# S32K324_M7 register map
Vendor: NXP Semiconductors; File version: 1.1
CPU: CM7 r0p1, little endian, MPU, FPU, VTOR, 4 interrupt priority bits
Registers are 32-bit, read-write, reset 0x0 unless marked. A register's access mark holds for its fields unless they carry their own. Offsets are from the block's base; [hi:lo] are bit positions; {n}, {i} and the like mark numbered series; 'fields as' and 'values as' point back to an identical list.

## VIRT_WRAPPER — VIRT_WRAPPER memory map
Base 0x402A8000
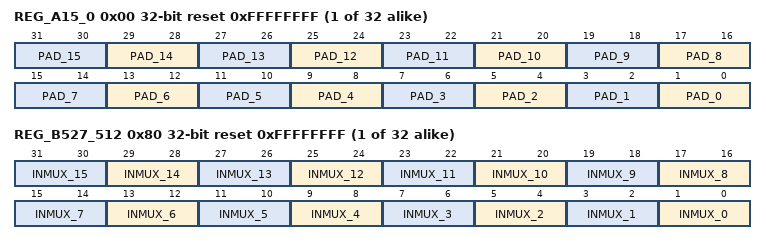
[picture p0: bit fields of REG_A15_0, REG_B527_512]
0x00 REG_A{x} (x=15_0,31_16,47_32,63_48,79_64,95_80,111_96,127_112,143_128,159_144,175_160,191_176,207_192,223_208,239_224,255_240,271_256,287_272,303_288,319_304,335_320,351_336,367_352,383_368,399_384,415_400,431_416,447_432,463_448,479_464,495_480,511_496; step 0x4) reset 0xFFFFFFFF — Parameter_n Register
  [2n+1:2n] PAD_{n} (n=0..15)
0x80 REG_B{x} (x=527_512,543_528,559_544,575_560,591_576,607_592,623_608,639_624,655_640,671_656,687_672,703_688,719_704,735_720,751_736,767_752,783_768,799_784,815_800,831_816,847_832,863_848,879_864,895_880,911_896,927_912,943_928,959_944,975_960,991_976,1007_992,1023_1008; step 0x4) reset 0xFFFFFFFF — Parameter_n Register
  [2n+1:2n] INMUX_{n} (n=0..15)
0x100 REG_C1039_1024 reset 0xFFFFFFFF — Parameter_n Register
  [1:0] INTC_CTRL — Interrupt register control
0x104 REG_D1055_1040 reset 0xFFFFFFFF — Parameter_n Register
  [31:30] REG_GCR — GCR Register Of REG_PROT

## WKPU
Base 0x402B4000
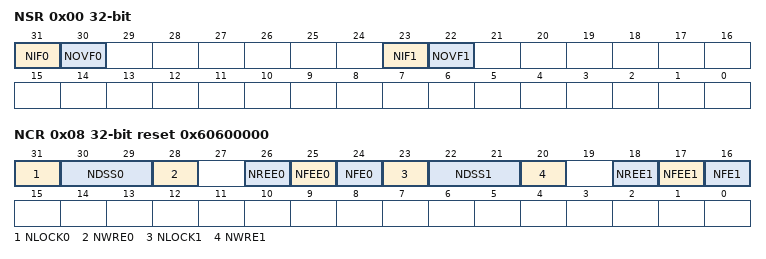
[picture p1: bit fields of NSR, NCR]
0x00 NSR write-1-clears — NMI Status Flag Register
  [31] NIF0 write-1-clears — NMI Status Flag 0
  [30] NOVF0 write-1-clears — NMI Overrun Status Flag 0
    0=No overrun has occurred on NMI input 0; 1=An overrun has occurred on NMI input 0
  [23] NIF1 write-1-clears — NMI Status Flag 1
    0=No event has occurred on the pad; 1=An event as defined by NREE1 and NFEE1 has occurred
  [22] NOVF1 write-1-clears — NMI Overrun Status Flag 1
    0=No overrun has occurred on NMI input 1; 1=An overrun has occurred on NMI input 1
0x08 NCR reset 0x60600000 — NMI Configuration Register
  [31] NLOCK0 — NMI Configuration Lock Register 0
  [30:29] NDSS0 — NMI Destination Source Select 0
    0=Non-maskable interrupt
  [28] NWRE0 — NMI Wakeup Request Enable 0
    0=System wakeup requests from the corresponding NIF0 field are disabled; 1=Causes a system wakeup request when NIF0 = 1 or NOVF0 = 1
  [26] NREE0 — NMI Rising-Edge Events Enable 0
    0=Rising-edge event is disabled; 1=Rising-edge event is enabled
  [25] NFEE0 — NMI Falling-edge Events Enable 0
  [24] NFE0 — NMI Filter Enable 0
    0=Filter is disabled; 1=Filter is enabled
  [23] NLOCK1 — NMI Configuration Lock Register 1
  [22:21] NDSS1 — NMI Destination Source Select 1
    0=Non-maskable interrupt
  [20] NWRE1 — NMI Wakeup Request Enable 1
    0=System wakeup requests from the corresponding NIF1 field are disabled; 1=Causes a system wakeup request when NIF1 = 1 or NOVF1 = 1
  [18] NREE1 — NMI Rising-Edge Events Enable 1
    values as NREE0
  [17] NFEE1 — NMI Falling-Edge Events Enable 1
  [16] NFE1 — NMI Filter Enable 1
    0=Filter is disabled; 1=Filter is enabled
0x14 WISR write-1-clears — Wakeup/Interrupt Status Flag Register
  [31:0] EIF write-1-clears — External Wakeup/Interrupt Status Flag x
0x18 IRER — Interrupt Request Enable Register
  [31:0] EIRE — External Interrupt Request Enable x
0x1C WRER — Wakeup Request Enable Register
  [31:0] WRE — External Wakeup Request Enable x
0x28 WIREER — Wakeup/Interrupt Rising-Edge Event Enable Register
  [31:0] IREE — External Interrupt Rising-edge Events Enable x
0x2C WIFEER — Wakeup/Interrupt Falling-Edge Event Enable Register
  [31:0] IFEEx — External Interrupt Falling-edge Events Enable x
0x30 WIFER — Wakeup/Interrupt Filter Enable Register
  [31:0] IFE — External Interrupt Filter Enable x
0x54 WISR_64 write-1-clears — Wakeup/Interrupt Status Flag Register
  [31:0] EIF_1 write-1-clears — External Wakeup/Interrupt Status Flag x
0x58 IRER_64 — Interrupt Request Enable Register
  [31:0] EIRE_1 — External Interrupt Request Enable x
0x5C WRER_64 — Wakeup Request Enable Register
  [31:0] WRE_1 — External Wakeup Request Enable x
0x68 WIREER_64 — Wakeup/Interrupt Rising-Edge Event Enable Register
  [31:0] IREE_1 — External Interrupt Rising-edge Events Enable x
0x6C WIFEER_64 — Wakeup/Interrupt Falling-Edge Event Enable Register
  [31:0] IFEEx_1 — External Interrupt Falling-edge Events Enable x
0x70 WIFER_64 — Wakeup/Interrupt Filter Enable Register
  [31:0] IFE_1 — External Interrupt Filter Enable x
